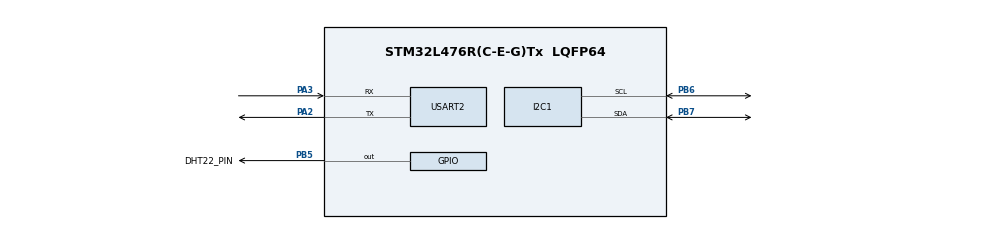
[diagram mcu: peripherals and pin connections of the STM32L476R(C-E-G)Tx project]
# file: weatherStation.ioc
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I2C1.Timing=0x00100D14
Mcu.Family=STM32L4
Mcu.Name=STM32L476R(C-E-G)Tx
Mcu.Package=LQFP64
NVIC.PriorityGroup=NVIC_PRIORITYGROUP_4
PA2.Mode=Asynchronous
PA2.Signal=USART2_TX
PA3.Mode=Asynchronous
PA3.Signal=USART2_RX
PB5.GPIO_Label=DHT22_PIN
PB5.Signal=GPIO_Output
PB6.Mode=I2C
PB6.Signal=I2C1_SCL
PB7.Mode=I2C
PB7.Signal=I2C1_SDA
ProjectManager.HeapSize=0x200
ProjectManager.StackSize=0x400
ProjectManager.TargetToolchain=STM32CubeIDE
RCC.HSE_VALUE=8000000
RCC.HSI_VALUE=16000000
RCC.LSE_VALUE=32768
RCC.MSI_VALUE=4000000
RCC.VCOOutputFreq_Value=32000000
USART2.VirtualMode-Asynchronous=VM_ASYNC
board=custom

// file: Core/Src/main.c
/* USER CODE BEGIN Header */
/**
  ******************************************************************************
  * @file           : main.c
  * @brief          : Main program body
  ******************************************************************************
  * @attention
  *
  * Copyright (c) 2025 STMicroelectronics.
  * All rights reserved.
  *
  * This software is licensed under terms that can be found in the LICENSE file
  * in the root directory of this software component.
  * If no LICENSE file comes with this software, it is provided AS-IS.
  *
  ******************************************************************************
  */
/* USER CODE END Header */
#include "main.h"

I2C_HandleTypeDef hi2c1;

UART_HandleTypeDef huart2;

void SystemClock_Config(void);
static void MX_GPIO_Init(void);
static void MX_USART2_UART_Init(void);
static void MX_I2C1_Init(void);

/* USER CODE BEGIN 0 */

int _write(int file, char *ptr, int len) {
	return HAL_UART_Transmit(&huart2, (uint8_t*)ptr, len, HAL_MAX_DELAY);
}

/* USER CODE END 0 */

int main(void)
{

  /* MCU Configuration--------------------------------------------------------*/

  /* Reset of all peripherals, Initializes the Flash interface and the Systick. */
  HAL_Init();

  /* Configure the system clock */
  SystemClock_Config();

  /* Initialize all configured peripherals */
  MX_GPIO_Init();
  MX_USART2_UART_Init();
  MX_I2C1_Init();
  /* USER CODE BEGIN 2 */

  lcd_send_string("Temperature: 79F\nAir Quality: N/A");

  while (1);                              // stop here

  /* USER CODE END 2 */

  /* Infinite loop */
  while (1)
  {

  }
}

void SystemClock_Config(void)
{
  RCC_OscInitTypeDef RCC_OscInitStruct = {0};
  RCC_ClkInitTypeDef RCC_ClkInitStruct = {0};

  /** Configure the main internal regulator output voltage
  */
  if (HAL_PWREx_ControlVoltageScaling(PWR_REGULATOR_VOLTAGE_SCALE1) != HAL_OK)
  {
    Error_Handler();
  }

  /** Initializes the RCC Oscillators according to the specified parameters
  * in the RCC_OscInitTypeDef structure.
  */
  RCC_OscInitStruct.OscillatorType = RCC_OSCILLATORTYPE_MSI;
  RCC_OscInitStruct.MSIState = RCC_MSI_ON;
  RCC_OscInitStruct.MSICalibrationValue = 0;
  RCC_OscInitStruct.MSIClockRange = RCC_MSIRANGE_6;
  RCC_OscInitStruct.PLL.PLLState = RCC_PLL_NONE;
  if (HAL_RCC_OscConfig(&RCC_OscInitStruct) != HAL_OK)
  {
    Error_Handler();
  }

  /** Initializes the CPU, AHB and APB buses clocks
  */
  RCC_ClkInitStruct.ClockType = RCC_CLOCKTYPE_HCLK|RCC_CLOCKTYPE_SYSCLK
                              |RCC_CLOCKTYPE_PCLK1|RCC_CLOCKTYPE_PCLK2;
  RCC_ClkInitStruct.SYSCLKSource = RCC_SYSCLKSOURCE_MSI;
  RCC_ClkInitStruct.AHBCLKDivider = RCC_SYSCLK_DIV1;
  RCC_ClkInitStruct.APB1CLKDivider = RCC_HCLK_DIV1;
  RCC_ClkInitStruct.APB2CLKDivider = RCC_HCLK_DIV1;

  if (HAL_RCC_ClockConfig(&RCC_ClkInitStruct, FLASH_LATENCY_0) != HAL_OK)
  {
    Error_Handler();
  }
}

static void MX_I2C1_Init(void)
{

  hi2c1.Instance = I2C1;
  hi2c1.Init.Timing = 0x00100D14;
  hi2c1.Init.OwnAddress1 = 0;
  hi2c1.Init.AddressingMode = I2C_ADDRESSINGMODE_7BIT;
  hi2c1.Init.DualAddressMode = I2C_DUALADDRESS_DISABLE;
  hi2c1.Init.OwnAddress2 = 0;
  hi2c1.Init.OwnAddress2Masks = I2C_OA2_NOMASK;
  hi2c1.Init.GeneralCallMode = I2C_GENERALCALL_DISABLE;
  hi2c1.Init.NoStretchMode = I2C_NOSTRETCH_DISABLE;
  if (HAL_I2C_Init(&hi2c1) != HAL_OK)
  {
    Error_Handler();
  }

  /** Configure Analogue filter
  */
  if (HAL_I2CEx_ConfigAnalogFilter(&hi2c1, I2C_ANALOGFILTER_ENABLE) != HAL_OK)
  {
    Error_Handler();
  }

  /** Configure Digital filter
  */
  if (HAL_I2CEx_ConfigDigitalFilter(&hi2c1, 0) != HAL_OK)
  {
    Error_Handler();
  }

}

static void MX_USART2_UART_Init(void)
{

  huart2.Instance = USART2;
  huart2.Init.BaudRate = 115200;
  huart2.Init.WordLength = UART_WORDLENGTH_8B;
  huart2.Init.StopBits = UART_STOPBITS_1;
  huart2.Init.Parity = UART_PARITY_NONE;
  huart2.Init.Mode = UART_MODE_TX_RX;
  huart2.Init.HwFlowCtl = UART_HWCONTROL_NONE;
  huart2.Init.OverSampling = UART_OVERSAMPLING_16;
  huart2.Init.OneBitSampling = UART_ONE_BIT_SAMPLE_DISABLE;
  huart2.AdvancedInit.AdvFeatureInit = UART_ADVFEATURE_NO_INIT;
  if (HAL_UART_Init(&huart2) != HAL_OK)
  {
    Error_Handler();
  }

}

static void MX_GPIO_Init(void)
{
  GPIO_InitTypeDef GPIO_InitStruct = {0};

  /* GPIO Ports Clock Enable */
  __HAL_RCC_GPIOA_CLK_ENABLE();
  __HAL_RCC_GPIOB_CLK_ENABLE();

  /*Configure GPIO pin Output Level */
  HAL_GPIO_WritePin(DHT22_PIN_GPIO_Port, DHT22_PIN_Pin, GPIO_PIN_RESET);

  /*Configure GPIO pin : DHT22_PIN_Pin */
  GPIO_InitStruct.Pin = DHT22_PIN_Pin;
  GPIO_InitStruct.Mode = GPIO_MODE_OUTPUT_PP;
  GPIO_InitStruct.Pull = GPIO_NOPULL;
  GPIO_InitStruct.Speed = GPIO_SPEED_FREQ_LOW;
  HAL_GPIO_Init(DHT22_PIN_GPIO_Port, &GPIO_InitStruct);

}

void Error_Handler(void)
{
  __disable_irq();
  while (1)
  {
  }
}
